# RL6678_IP_SVD register map
Vendor: Realtek
IP svd file
Registers are 32-bit, read-write, reset 0x0 unless marked. A register's access mark holds for its fields unless they carry their own. Offsets are from the block's base; lines under a group give offsets from that group; [hi:lo] are bit positions; {n}, {i} and the like mark numbered series; 'fields as' and 'values as' point back to an identical list; <NAME> marks a mode.

## Memory map
0x08000000 SPI_FLASH size 0x1D4
0x40000000 PAGE0 size 0x100
0x40000000 PAGE1 size 0x1200
0x40000000 PAGE2 size 0x300
0x40000000 PAGE3 size 0x1310
0x40000000 PAGE4 size 0x14A4
0x40000000 PAGE5 size 0x15AC
0x40000000 PAGE6 size 0x1700
0x40000000 PAGE7 size 0x800
0x40000000 PAGE12 size 0x1300
0x40000000 PAGE17 size 0x1800
0x40000000 PAGE26 size 0x261C
0x40000000 TXPWR_CTRL size 0xDB04
0x400C0000 AES_REG size 0x1018
0x400C8000 SHA_REG size 0x1018
0x400D8000 LCDC_REG size 0xD8
0x400E0000 GDMA0_REG size 0x400
0x400E8000 SPI0_REG size 0xB0C
0x400E9000 SPI1_REG size 0xB0C
0x400EA000 MIPI_DSI_REG size 0xC10
0x400EB000 RSA_REG size 0xF30
0x400EC000 ED25519_REG size 0x204
0x400ED000 ECDSA_REG size 0x204
0x400EE000 IR_REG size 0x30
0x400EF000 I2C1_REG size 0x100
0x400F0000 I2C2_REG size 0x100
0x400F2000 ZIGBEE_REG size 0x28
0x41000000 HP_SYS size 0x200
0x41000440 WDG2_REG size 0x10
0x410004C0 WDG4_REG size 0x10
0x41000500 IPCNP_REG size 0x14
0x41000580 IPCAP_REG size 0x14
0x41002000 PSRAM_PHY_REG size 0xFC
0x41004000 UART0_REG size 0x60
0x41005000 UART1_REG size 0x60
0x41006000 UART2_REG size 0x60
0x41007000 UART3_REG size 0x60
0x41008000 LEDC_REG size 0x34
0x41009000 TRNG_REG size 0x1BC
0x4100A000 TIMER8_REG size 0x6C
0x4100A200 TIMER9_REG size 0x6C
0x4100A400 TIMER10_REG size 0x6C
0x4100A600 TIMER11_REG size 0x6C
0x4100A800 TIMER12_REG size 0x6C
0x4100AA00 TIMER13_REG size 0x6C
0x4100B000 AUDIO_REG size 0x908
0x4100C000 VAD_REG size 0x64
0x4100C100 AUD_REG size 0x30
0x4100D000 SPORT0_REG size 0x984
0x4100E000 SPORT1_REG size 0x984
0x4100F000 SPORT2_REG size 0x984
0x41010000 SPORT3_REG size 0x984
0x41011000 DDRPHY_REG size 0x600
0x41012000 PSRAM_REG size 0x1D4
0x41100000 DDRC_REG size 0x4A4
0x41101000 DDRCF_REG size 0x9A0
0x42000000 OTPC_REG size 0x740
0x42008000 AON size 0x100
0x42008100 REGU_REG size 0xB0
0x42008200 LP_SYS size 0x100
0x42008300 PMC_REG size 0x100
0x42008400 WDG0_REG size 0x10
0x42008600 IPCLP_REG size 0x14
0x42008800 XTAL size 0x3C
0x42008840 PLL_REG size 0x40
0x42008880 SWR1_REG size 0x40
0x420088C0 SWR2_REG size 0x40
0x42008900 WLAFE size 0x3C
0x42008A00 PINMUX_REG size 0x1FC
0x42008C00 RSIP_REG size 0x130
0x42008E00 SDM_REG size 0x20
0x42009000 DBGTIM_REG size 0x14
0x42009200 MEM_CTRL size 0x148
{0x4200B000+0x200*n} TIMER{n}_REG size 0x6C (n=0..7)
0x4200C000 UARTLOG_REG size 0x78
0x4200D000 GPIO_REG size 0x7C
0x4200E000 RTC size 0x28
0x4200F000 I2C0_REG size 0x100
0x42010000 CTC_REG size 0x414
0x42012000 ADC_REG size 0xB0
0x42012800 CMP_REG size 0x4C
0x42013000 THERMAL_REG size 0x30
0x44000000 SPI_FLASH_CTRL size 0x1D4
0x51000400 WDG1_REG_S size 0x10
0x51000480 WDG3_REG_S size 0x10

## SDM_REG
Base 0x42008E00
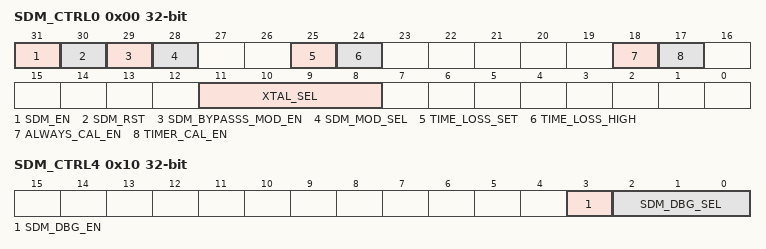
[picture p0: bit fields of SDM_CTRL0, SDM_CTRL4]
0x00 SDM_CTRL0 — SDM Control Register
  [31] SDM_EN — Enable SDM
  [30] SDM_RST — 0: Reset SDM
  [29] SDM_BYPASSS_MOD_EN — Bypass mode enable
  [28] SDM_MOD_SEL — 0: Default mode 1: User-defined parameter mode
  [25] TIME_LOSS_SET — Time loss set 1: User-defined
  [24] TIME_LOSS_HIGH — Decide 32k output compensation direction 1: Mask 0: Add
  [18] ALWAYS_CAL_EN — 1: Enable always_cal
  [17] TIMER_CAL_EN — 1: Enable timer_cal
  [11:8] XTAL_SEL — XTAL frequency select, default 40M * 4'h0: XTAL40M * 4'h1: XTAL25M * 4'h4: XTAL20M * 4'h5: XTAL26M * 4'hD: XTAL27M * 4'hE: XTAL24M
0x04 SDM_CTRL1 — Config observed 128K cycle
  [15:0] SDM_OBS_CYC — Set observed 128k cycle, default 1024 128k cycles
0x08 SDM_CTRL2 — Set ref counter value
  [31:0] SDM_OBS_REF_CYC — Set in observed cycles, refer to counters value, default 312500 XTAL cycles
0x0C SDM_CTRL3 — Set XTAL period
  [31:0] XTAL_PERIOD — Set reference xtal period (ns)
0x10 SDM_CTRL4 — SDM Debug Register
  [3] SDM_DBG_EN — 1: Enable SDM debug
  [2:0] SDM_DBG_SEL — Set in observed cycles, refer to counters value
0x14 SDM_CTRL5 — Time loss Set
  [31:0] TIME_LOSS_REG — Source clock time loss every cycle
0x1C SDM_TIMEOUT reset 0x2000000 — Set Timer Trigger Counter Value
  [31:0] TIMEOUT_CNT — Set SDM timer trigger calibration timeout value

## Notices in the file
Copyright (C) 2012-2025 Realsil Limited. All rights reserved.
